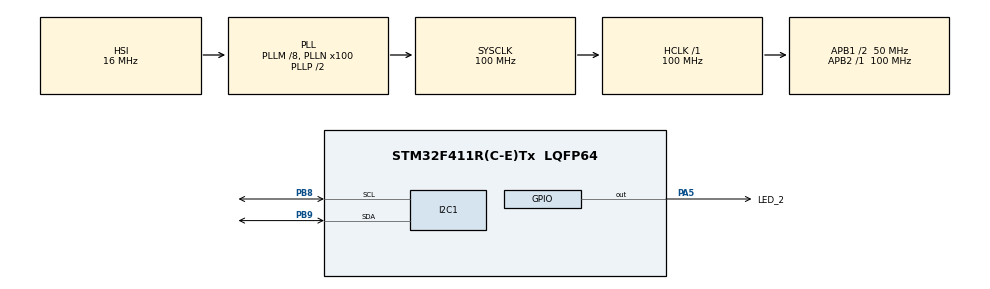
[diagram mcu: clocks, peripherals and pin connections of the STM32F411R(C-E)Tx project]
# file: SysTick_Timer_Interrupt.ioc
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Mcu.Family=STM32F4
Mcu.Name=STM32F411R(C-E)Tx
Mcu.Package=LQFP64
NVIC.PriorityGroup=NVIC_PRIORITYGROUP_4
NVIC.RCC_IRQn=true\:0\:0\:false\:false\:true\:true\:false\:true
PA5.GPIO_Label=LED_2
PA5.Signal=GPIO_Output
PB8.Mode=I2C
PB8.Signal=I2C1_SCL
PB9.Mode=I2C
PB9.Signal=I2C1_SDA
ProjectManager.HeapSize=0x200
ProjectManager.StackSize=0x400
ProjectManager.TargetToolchain=STM32CubeIDE
RCC.48MHZClocksFreq_Value=50000000
RCC.AHBFreq_Value=100000000
RCC.APB1CLKDivider=RCC_HCLK_DIV2
RCC.APB1Freq_Value=50000000
RCC.APB1TimFreq_Value=100000000
RCC.APB2Freq_Value=100000000
RCC.APB2TimFreq_Value=100000000
RCC.CortexFreq_Value=100000000
RCC.HCLKFreq_Value=100000000
RCC.HSE_VALUE=25000000
RCC.HSI_VALUE=16000000
RCC.LSE_VALUE=32768
RCC.PLLM=8
RCC.PLLN=100
RCC.RCC_TIM_PRescaler_Selection=RCC_TIMPRES_DESACTIVATED
RCC.SYSCLKFreq_VALUE=100000000
RCC.SYSCLKSource=RCC_SYSCLKSOURCE_PLLCLK
RCC.VCOOutputFreq_Value=200000000
board=custom

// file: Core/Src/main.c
/* USER CODE BEGIN Header */
/**
  ******************************************************************************
  * @file           : main.c
  * @brief          : Main program body
  ******************************************************************************
  * @attention
  *
  * Copyright (c) 2024 STMicroelectronics.
  * All rights reserved.
  *
  * This software is licensed under terms that can be found in the LICENSE file
  * in the root directory of this software component.
  * If no LICENSE file comes with this software, it is provided AS-IS.
  *
  ******************************************************************************
  */
/* USER CODE END Header */
#include "main.h"

/* USER CODE BEGIN Includes */
#include <stdbool.h>

/* USER CODE END Includes */

/* USER CODE BEGIN PD */
#define TIME_CHANGE_STATE (750 - 1)

/* USER CODE END PD */

I2C_HandleTypeDef hi2c1;

/* USER CODE BEGIN PV */
uint16_t count_SysTick;

/* USER CODE END PV */

void SystemClock_Config(void);
static void MX_GPIO_Init(void);
static void MX_I2C1_Init(void);

int main(void)
{

  /* MCU Configuration--------------------------------------------------------*/

  /* Reset of all peripherals, Initializes the Flash interface and the Systick. */
  HAL_Init();

  /* Configure the system clock */
  SystemClock_Config();

  /* Initialize all configured peripherals */
  MX_GPIO_Init();
  MX_I2C1_Init();
  /* USER CODE BEGIN 2 */
  lcd_init();		   // Initialize LCD
  lcd_backlight(true); // Turns on backlight

  char *text_1 = "STM32";
  char *text_2 = "DEVELOPMENT";

  /* USER CODE END 2 */

  /* Infinite loop */
  /* USER CODE BEGIN WHILE */
  while (true)
  {
    /* USER CODE END WHILE */

    /* USER CODE BEGIN 3 */
	if(count_SysTick > TIME_CHANGE_STATE)
	{
		HAL_GPIO_TogglePin(LED_2_GPIO_Port, LED_2_Pin);
		count_SysTick = 0;

		lcd_sweep_string(text_1, 0, 5, true);
		lcd_sweep_string(text_2, 1, 3, false);
	}

  }
  /* USER CODE END 3 */
}

void SystemClock_Config(void)
{
  RCC_OscInitTypeDef RCC_OscInitStruct = {0};
  RCC_ClkInitTypeDef RCC_ClkInitStruct = {0};

  /** Configure the main internal regulator output voltage
  */
  __HAL_RCC_PWR_CLK_ENABLE();
  __HAL_PWR_VOLTAGESCALING_CONFIG(PWR_REGULATOR_VOLTAGE_SCALE1);

  /** Initializes the RCC Oscillators according to the specified parameters
  * in the RCC_OscInitTypeDef structure.
  */
  RCC_OscInitStruct.OscillatorType = RCC_OSCILLATORTYPE_HSI;
  RCC_OscInitStruct.HSIState = RCC_HSI_ON;
  RCC_OscInitStruct.HSICalibrationValue = RCC_HSICALIBRATION_DEFAULT;
  RCC_OscInitStruct.PLL.PLLState = RCC_PLL_ON;
  RCC_OscInitStruct.PLL.PLLSource = RCC_PLLSOURCE_HSI;
  RCC_OscInitStruct.PLL.PLLM = 8;
  RCC_OscInitStruct.PLL.PLLN = 100;
  RCC_OscInitStruct.PLL.PLLP = RCC_PLLP_DIV2;
  RCC_OscInitStruct.PLL.PLLQ = 4;
  if (HAL_RCC_OscConfig(&RCC_OscInitStruct) != HAL_OK)
  {
    Error_Handler();
  }

  /** Initializes the CPU, AHB and APB buses clocks
  */
  RCC_ClkInitStruct.ClockType = RCC_CLOCKTYPE_HCLK|RCC_CLOCKTYPE_SYSCLK
                              |RCC_CLOCKTYPE_PCLK1|RCC_CLOCKTYPE_PCLK2;
  RCC_ClkInitStruct.SYSCLKSource = RCC_SYSCLKSOURCE_PLLCLK;
  RCC_ClkInitStruct.AHBCLKDivider = RCC_SYSCLK_DIV1;
  RCC_ClkInitStruct.APB1CLKDivider = RCC_HCLK_DIV2;
  RCC_ClkInitStruct.APB2CLKDivider = RCC_HCLK_DIV1;

  if (HAL_RCC_ClockConfig(&RCC_ClkInitStruct, FLASH_LATENCY_3) != HAL_OK)
  {
    Error_Handler();
  }
}

static void MX_I2C1_Init(void)
{

  hi2c1.Instance = I2C1;
  hi2c1.Init.ClockSpeed = 100000;
  hi2c1.Init.DutyCycle = I2C_DUTYCYCLE_2;
  hi2c1.Init.OwnAddress1 = 0;
  hi2c1.Init.AddressingMode = I2C_ADDRESSINGMODE_7BIT;
  hi2c1.Init.DualAddressMode = I2C_DUALADDRESS_DISABLE;
  hi2c1.Init.OwnAddress2 = 0;
  hi2c1.Init.GeneralCallMode = I2C_GENERALCALL_DISABLE;
  hi2c1.Init.NoStretchMode = I2C_NOSTRETCH_DISABLE;
  if (HAL_I2C_Init(&hi2c1) != HAL_OK)
  {
    Error_Handler();
  }

}

static void MX_GPIO_Init(void)
{
  GPIO_InitTypeDef GPIO_InitStruct = {0};

  /* GPIO Ports Clock Enable */
  __HAL_RCC_GPIOA_CLK_ENABLE();
  __HAL_RCC_GPIOB_CLK_ENABLE();

  /*Configure GPIO pin Output Level */
  HAL_GPIO_WritePin(LED_2_GPIO_Port, LED_2_Pin, GPIO_PIN_RESET);

  /*Configure GPIO pin : LED_2_Pin */
  GPIO_InitStruct.Pin = LED_2_Pin;
  GPIO_InitStruct.Mode = GPIO_MODE_OUTPUT_PP;
  GPIO_InitStruct.Pull = GPIO_NOPULL;
  GPIO_InitStruct.Speed = GPIO_SPEED_FREQ_LOW;
  HAL_GPIO_Init(LED_2_GPIO_Port, &GPIO_InitStruct);

}

void Error_Handler(void)
{
  __disable_irq();
  while (1)
  {
  }
}
